# NAVSS0_DMA_VIRTID_0_NAV_DDR0_VIRTID_CFG_MMRS register map
Vendor: Texas Instruments
Peripheral module from a debugger description file (folder J721S2).
Registers are 32-bit, read-only, reset 0x66382100 unless marked. A register's access mark holds for its fields unless they carry their own. Offsets are as the file gives them; lines under a group give offsets from that group; [hi:lo] are bit positions; {n}, {i} and the like mark numbered series; 'fields as' and 'values as' point back to an identical list; <NAME> marks a mode.

## NAVSS0_DMA_VIRTID_0_NAV_DDR0_VIRTID_CFG_MMRS
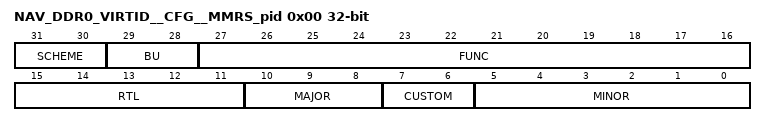
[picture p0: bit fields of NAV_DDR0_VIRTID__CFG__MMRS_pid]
0x00 NAV_DDR0_VIRTID__CFG__MMRS_pid — The Revision Register contains the major and minor revisions for the module.
  [31:30] SCHEME — PID register scheme
  [29:28] BU — Business Unit: 10 = Processors
  [27:16] FUNC — Module ID
  [15:11] RTL — RTL revision. Will vary depending on release.
  [10:8] MAJOR — Major revision
  [7:6] CUSTOM
  [5:0] MINOR — Minor revision
0x10 NAV_DDR0_VIRTID__CFG__MMRS_window rw reset 0x0 — The VirtID for window a.
  [11:0] VIRTID — VirtID for window a.
